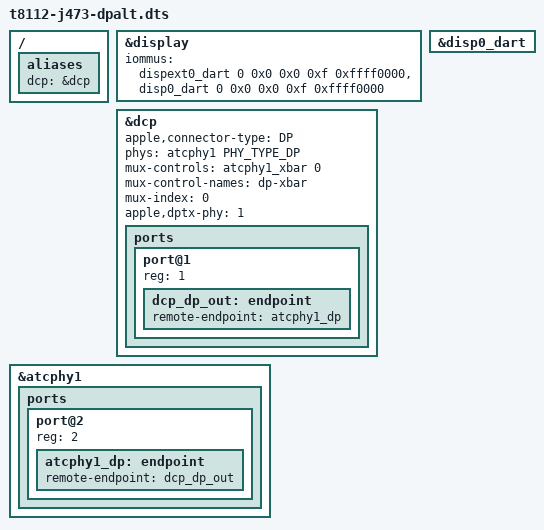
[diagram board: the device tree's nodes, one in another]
// SPDX-License-Identifier: GPL-2.0+ OR MIT
/*
 * Apple Mac mini (M2, 2023), with DisplayPort alternate mode on the
 * back-right USB-C port
 *
 * target-type: J473
 *
 * The HDMI port stays on DCPext. DCP (disp0), which is unused on this
 * machine otherwise, drives DisplayPort through atcphy1 to the USB-C
 * port of hpm1. The Type-C port controller sets the PHY mode and reports
 * HPD.
 *
 * Bring-up only: DisplayPort does not survive system suspend yet, because
 * neither the display crossbar nor atcphy restore their state on resume.
 *
 * Copyright The Asahi Linux Contributors
 */

#include "t8112-j473.dts"

/ {
	aliases {
		/*
		 * The loader sets up the DCP firmware and carveouts for it, and
		 * fails the boot if it cannot.
		 */
		dcp = &dcp;
	};
};

/*
 * The loader maps the framebuffer through, and locks, the first DART here,
 * which must be dispext0 for the HDMI framebuffer.
 */
&display {
	iommus = <&dispext0_dart 0 0x0 0x0 0xf 0xffff0000>,
		 <&disp0_dart 0 0x0 0x0 0xf 0xffff0000>;
};

&disp0_dart {
	status = "okay";
};

&dcp {
	/* enabled by the loader */
	apple,connector-type = "DP";

	phys = <&atcphy1 PHY_TYPE_DP>;
	phy-names = "dp-phy";
	mux-controls = <&atcphy1_xbar 0>;
	mux-control-names = "dp-xbar";
	mux-index = <0>;
	apple,dptx-phy = <1>;

	ports {
		port@1 {
			reg = <1>;

			dcp_dp_out: endpoint {
				remote-endpoint = <&atcphy1_dp>;
			};
		};
	};
};

&atcphy1 {
	ports {
		port@2 {
			reg = <2>;

			atcphy1_dp: endpoint {
				remote-endpoint = <&dcp_dp_out>;
			};
		};
	};
};
